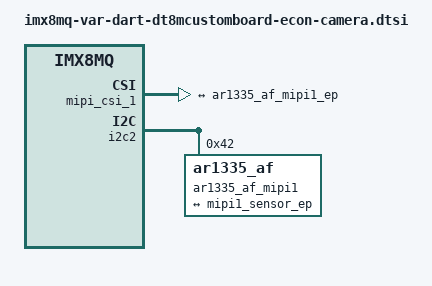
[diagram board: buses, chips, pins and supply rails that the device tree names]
// SPDX-License-Identifier: (GPL-2.0 OR MIT)
/*
 * Copyright 2017 NXP
 * Copyright 2018-2021 Variscite Ltd.
 */

&csi1_bridge {
	fsl,two-8bit-sensor-mode;
	yuv-double-component;
	yu-swap;
};

&mipi_csi_1 {
	#address-cells = <1>;
	#size-cells = <0>;
	rxhs-settle = <23>;
	status = "okay";

	/* When the second clock is changed, the link-frequencies entry in
	 * the basler_camera_mipi1_ep node also needs to be updated. */
	assigned-clock-rates = <266000000>, <150000000>, <66000000>;
	port {
		mipi1_sensor_ep: endpoint@0 {
			remote-endpoint = <&ar1335_af_mipi1_ep>;
			clock-lanes = <0>;
			data-lanes = <1 2 3 4>;
		};
	};
};

&i2c2 {

	/delete-node/ov5640_mipi1@3c;

	ar1335_af_mipi1: ar1335_af_mipi1@42 {
		status = "okay";
		compatible = "ar1335_af";
		reg = <0x42>;
		clocks = <&clk IMX8MQ_CLK_CLKO2>;
		clock-names = "csi_mclk";
		camera_mipi_lanes = <4>;
		csi_id = <0>;
		mclk = <24000000>;
		mclk_source = <0>;
		port {
			ar1335_af_mipi1_ep: endpoint {
				remote-endpoint = <&mipi1_sensor_ep>;
			};
		};
	};
};
